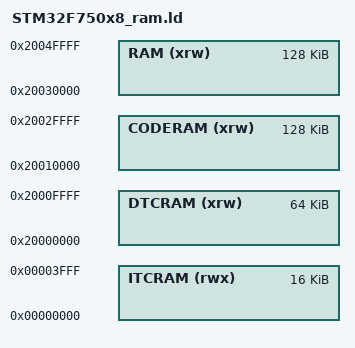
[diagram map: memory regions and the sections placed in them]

MEMORY
{
  ITCRAM (rwx) :  ORIGIN = 0x00000000, LENGTH = 16K
  DTCRAM (xrw) :  ORIGIN = 0x20000000, LENGTH = 64K

  CODERAM(xrw) :  ORIGIN = 0x20010000, LENGTH = 128K
  RAM(xrw)     :  ORIGIN = 0x20030000, LENGTH = 128K
}

REGION_ALIAS("TEXT", CODERAM);
REGION_ALIAS("RAM2", RAM);

INCLUDE armm_default_noflash.ld

